VERSION ""

NS_ :

BS_:

BU_: VCU MOTOR BMS DEBUG

// ============================================
// Message Definitions
// ============================================

// 0x201: Motor Torque Command (VCU -> MOTOR)
// Fixed length to 3 bytes
BO_ 513 MOTOR_TorqueCmd: 3 VCU
 SG_ CommandByte : 0|8@1+ (1,0) [0|255] "" MOTOR
 SG_ Torque : 8|16@1- (1,0) [-32768|32767] "Nm" MOTOR

// 0x300: Debug State Message (VCU -> DEBUG)
BO_ 768 VCU_State: 2 VCU
 SG_ StatusByte : 0|8@1+ (1,0) [0|255] "" DEBUG
 SG_ Reserved : 8|8@1+ (1,0) [0|0] "" DEBUG

// 0x301: Debug Pedals Message (VCU -> DEBUG)
// Byte Order: @1 indicates Intel (Little Endian)
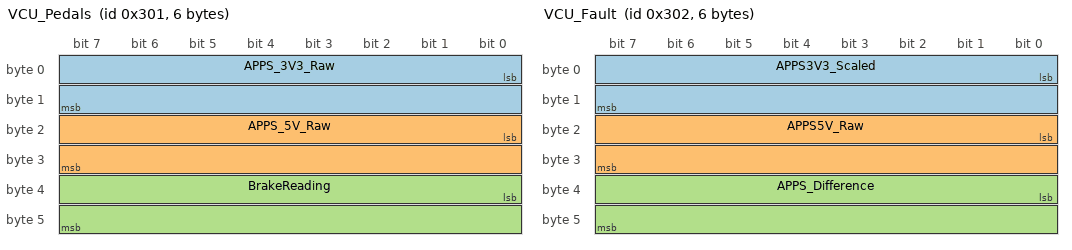
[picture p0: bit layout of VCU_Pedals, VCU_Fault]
BO_ 769 VCU_Pedals: 6 VCU
 SG_ APPS_3V3_Raw : 0|16@1+ (1,0) [0|1023] "raw" DEBUG
 SG_ APPS_5V_Raw : 16|16@1+ (1,0) [0|1023] "raw" DEBUG
 SG_ BrakeReading : 32|16@1+ (1,0) [0|1023] "raw" DEBUG

// 0x302: Debug Fault Message (VCU -> DEBUG)
BO_ 770 VCU_Fault: 6 VCU
 SG_ APPS3V3_Scaled : 0|16@1+ (1,0) [0|1023] "scaled" DEBUG
 SG_ APPS5V_Raw : 16|16@1+ (1,0) [0|1023] "raw" DEBUG
 SG_ APPS_Difference : 32|16@1+ (1,0) [0|1023] "units" DEBUG

// ============================================
// Value Tables
// ============================================

// Vehicle State values
VAL_ 768 StatusByte 3 "DRIVE" 2 "BUZZIN" 1 "STARTIN" 0 "INIT";

// Comments
CM_ BO_ 513 "Motor torque command from VCU to motor controller. CommandByte=0x90.";
CM_ BO_ 768 "VCU state info. Status byte packs state, brake, BMS, and fault.";
CM_ BO_ 769 "Raw pedal readings for debugging.";
CM_ BO_ 770 "APPS fault information. Sent when sensors differ by >10%.";
